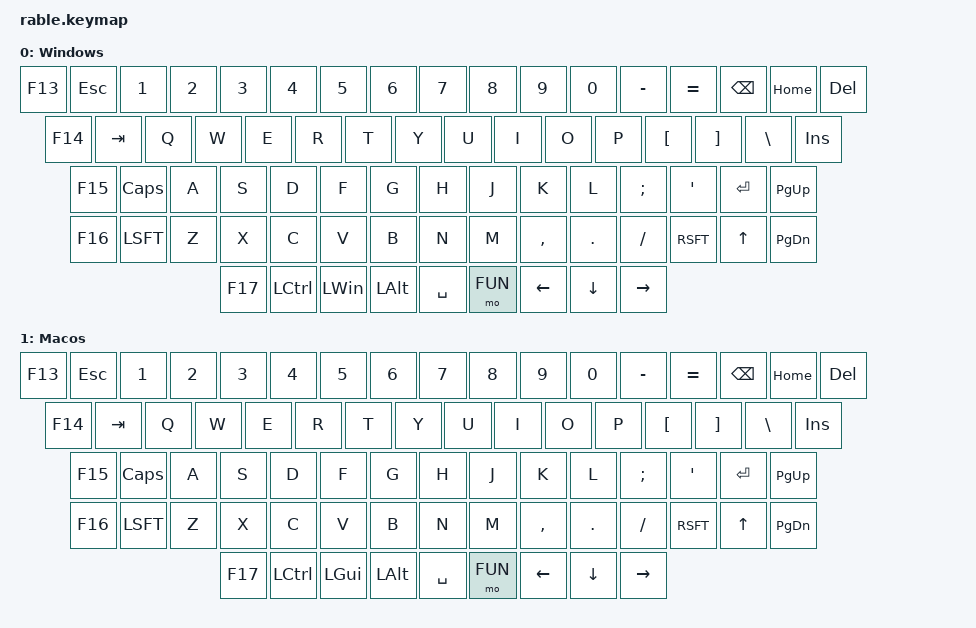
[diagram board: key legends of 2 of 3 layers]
/*
 * SPDX-License-Identifier: MIT
 */

#include <behaviors.dtsi>
#include <dt-bindings/zmk/keys.h>
#include <dt-bindings/zmk/bt.h>
#include <dt-bindings/zmk/outputs.h>
#include <dt-bindings/zmk/rgb.h>
#include <dt-bindings/zmk/ext_power.h>

#define BASE_WIN 0
#define BASE_MAC 1
#define FUN 2

#define XXX &none
#define ___ &trans

&lt {
    tapping-term-ms = <400>;
};

/ {
     keymap {
        compatible = "zmk,keymap";
        

        default_layer {
            label = "Windows";

            bindings = <
    &kp F13 &kp ESC &kp NUM_1 &kp NUM_2 &kp NUM_3 &kp NUM_4 &kp NUM_5 &kp NUM_6 &kp NUM_7 &kp NUM_8 &kp NUM_9 &kp NUM_0 &kp MINUS &kp EQL  &kp BSPC &kp HOME  &kp DEL
    &kp F14 &kp TAB &kp Q &kp W &kp E &kp R &kp T &kp Y &kp U &kp I &kp O &kp P &kp LBKT &kp RBKT &kp BSLH &kp INS
    &kp F15 &kp CAPS &kp A &kp S &kp D &kp F &kp G &kp H &kp J &kp K &kp L &kp SCLN &kp QUOT &kp RET &kp PG_UP
    &kp F16 &kp LSFT &kp Z &kp X &kp C &kp V &kp B &kp N &kp M &kp CMMA &kp DOT &kp FSLH &kp RSFT &kp UP &kp PG_DN
    &kp F17 &kp LCTL &kp LWIN &kp LALT &kp SPC &mo FUN &kp LEFT &kp DOWN &kp RIGHT
            >;

            sensor-bindings = <&inc_dec_kp C_VOL_UP C_VOL_DN>;
        };

        macos {
            label = "Macos";

            bindings = <
    &kp F13 &kp ESC &kp NUM_1 &kp NUM_2 &kp NUM_3 &kp NUM_4 &kp NUM_5 &kp NUM_6 &kp NUM_7 &kp NUM_8 &kp NUM_9 &kp NUM_0 &kp MINUS &kp EQL  &kp BSPC &kp HOME  &kp DEL
    &kp F14 &kp TAB &kp Q &kp W &kp E &kp R &kp T &kp Y &kp U &kp I &kp O &kp P &kp LBKT &kp RBKT &kp BSLH &kp INS
    &kp F15 &kp CAPS &kp A &kp S &kp D &kp F &kp G &kp H &kp J &kp K &kp L &kp SCLN &kp QUOT &kp RET &kp PG_UP
    &kp F16 &kp LSFT &kp Z &kp X &kp C &kp V &kp B &kp N &kp M &kp CMMA &kp DOT &kp FSLH &kp RSFT &kp UP &kp PG_DN
    &kp F17 &kp LCTL &kp LGUI &kp LALT &kp SPC &mo FUN &kp LEFT &kp DOWN &kp RIGHT
            >;

            sensor-bindings = <&inc_dec_kp C_VOL_UP C_VOL_DN>;
        };

        functions {
            label = "Functions";

            bindings = <
    XXX &ext_power EP_TOG &kp F1 &kp F2 &kp F3 &kp F4 &kp F5 &kp F6 &kp F7 &kp F8 &kp F9 &kp F10 &kp F11 &kp F12 &reset &kp DEL ___
    XXX &bt BT_SEL 0 &bt BT_SEL 1 &bt BT_SEL 2 &bt BT_SEL 3 &bt BT_SEL 4 ___ ___ ___ ___ ___ ___ ___ &out OUT_BLE &out OUT_USB ___ 
    XXX &tog BASE_MAC &rgb_ug RGB_TOG &rgb_ug RGB_EFF &rgb_ug RGB_HUD &rgb_ug RGB_HUI &rgb_ug RGB_BRD &rgb_ug RGB_BRI ___ ___ ___ ___ ___ &bootloader ___
    XXX ___ ___ ___ ___ ___ ___ ___ ___ ___ ___ ___ ___ ___ ___
    XXX ___ ___ ___ &reset XXX ___ ___ ___ ___
            >;

            sensor-bindings = <&inc_dec_kp C_NEXT C_PREV>;
        };

    };

    // Uncomment to enable the encoder.
   
};

